# HSM_DCC0_HSM_DCC0 register map
Vendor: Texas Instruments
Peripheral module from a debugger description file (folder AM263).
Registers are 32-bit, read-write, reset 0x0 unless marked. A register's access mark holds for its fields unless they carry their own. Offsets are as the file gives them; lines under a group give offsets from that group; [hi:lo] are bit positions; {n}, {i} and the like mark numbered series; 'fields as' and 'values as' point back to an identical list; <NAME> marks a mode.

## HSM_DCC0_HSM_DCC0
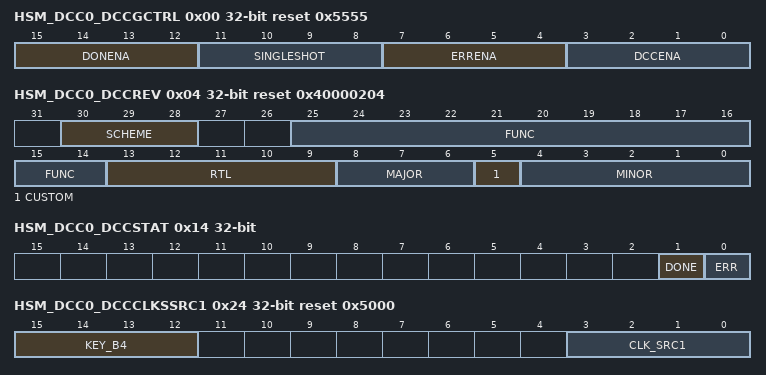
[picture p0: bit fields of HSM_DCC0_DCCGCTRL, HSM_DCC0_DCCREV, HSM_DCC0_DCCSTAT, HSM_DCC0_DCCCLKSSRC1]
0x00 HSM_DCC0_DCCGCTRL reset 0x5555
  [15:12] DONENA — The DONEENA bit enables/disables the done signal. 0101 = disabled & 1010 = enabled
  [11:8] SINGLESHOT — Single/Continuous checking mode. 0101 = Continuous & 1010 = Single
  [7:4] ERRENA — The ERRENA bit enables/disables the error signal. 0101 = disabled & 1010 = enabled
  [3:0] DCCENA — The DCCENA bit starts and stops the operation of the dcc 0101 = disabled & 1010 = enabled
0x04 HSM_DCC0_DCCREV ro reset 0x40000204
  [30:28] SCHEME — SCHEME. - (RO )
  [25:14] FUNC — Functional release number - (RO )
  [13:9] RTL — Design Release Number - (RO )
  [8:6] MAJOR — Major Revision Number - (RO )
  [5] CUSTOM — Indicates a special version of the module. May not be supported by standard software - (RO )
  [4:0] MINOR — Minor revision number. - (RO )
0x08 HSM_DCC0_DCCCNTSEED0
  [19:0] COUNTSEED0 — The seed value for Counter 0. The seed value that gets loaded into counter 0 (clock source 0)
0x0C HSM_DCC0_DCCVALIDSEED0
  [15:0] VALIDSEED0 — The seed value for Valid Duration Counter 0.The seed value that gets loaded into the valid duration counter for clock source 0
0x10 HSM_DCC0_DCCCNTSEED1
  [19:0] COUNTSEED1 — The seed value for Counter 1. The seed value that gets loaded into counter 1 (clock source 1
0x14 HSM_DCC0_DCCSTAT
  [1] DONE — Indicates whether or not an done has occured. Writing a 1 to this bit clears the flag.
  [0] ERR — Indicates whether or not an error has occured. Writing a 1 to this bit clears the flag.
0x18 HSM_DCC0_DCCCNT0 ro
  [19:0] COUNT0 — This field contains the current value of counter 0. - (RO )
0x1C HSM_DCC0_DCCVALID0 ro
  [15:0] VALID0 — This field contains the current value of valid counter 0. - (RO )
0x20 HSM_DCC0_DCCCNT1 ro
  [19:0] COUNT1 — This field contains the current value of counter 1. - (RO )
0x24 HSM_DCC0_DCCCLKSSRC1 reset 0x5000
  [15:12] KEY_B4 — Key Programing (1010 is the KEY Value)
  [3:0] CLK_SRC1 — Clock source selection for Source 0DCC-A Clock source-0 selection Program value and its respective clock selected 0x0 - REF_CLK0x1 - CPU_CLK0x2 - RC_CLK0x3 - RC_CLK0x4 - RC_CLK0x5 - RC_CLK0x6 - RC_CLK0x7 - RC_CLKDCC-B Clock source-0 selection Program value and its respective clock selected 0x0 - VCLK0x1 - DSS_CLK0x2 - BSS_CLK0x3 - QSPI_CLK0x4 - FDCAN_CLK0x5 - REF_CLK0x6 - CPU_CLK0x7 - RC_CLK
0x28 HSM_DCC0_DCCCLKSSRC0 reset 0x5
  [3:0] CLK_SRC0 — Clock source selection for Source 0DCC-A Clock source-0 selection Program value and its respective clock selected 0 - REF_CLKA - PLL_6005 - PLL_240DCC-B Clock source-0 selection Program value and its respective clock selected 0 - PLL_600A - VCLK5 - CPU_CLK
